# RTS5918 register map
Vendor: Realtek Semiconductor Corp.; Series: RTS5918 Series; File version: 1.00
CPU: ARMV8MML r0p0, little endian, MPU, FPU, VTOR, 3 interrupt priority bits, 8 SAU regions
Registers are 32-bit, read-write, reset 0x0 unless marked. A register's access mark holds for its fields unless they carry their own. Offsets are from the block's base; [hi:lo] are bit positions; {n}, {i} and the like mark numbered series; 'fields as' and 'values as' point back to an identical list.

## PWMLED0 — PWMLED Controller
Base 0x40253D00
Same registers: PWMLED1 0x40253E00
0x00 MODE
  [1:0] SEL — Mode Selection
    0=OFF (PWMLED ouput is off); 1=BREATHING (PWMLED is under breathing mode); 2=BLINKING (PWMLED is under blinking mode); 3=ALWAYS_ON (PWMLED ouput is always on)
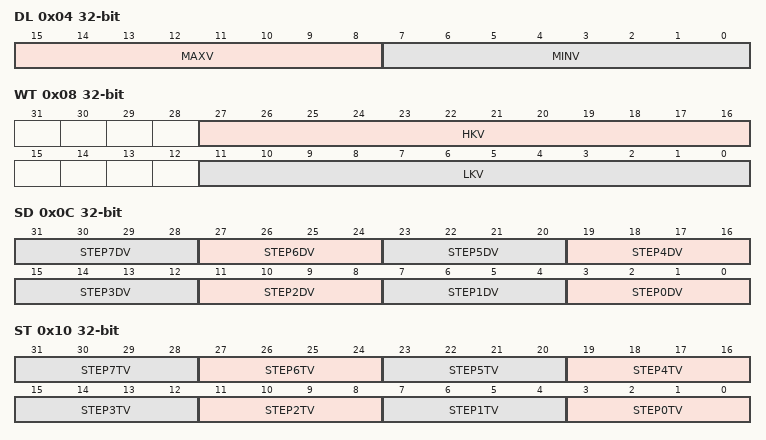
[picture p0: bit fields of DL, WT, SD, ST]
0x04 DL — DUTY LIMIT REGISTER
  [15:8] MAXV — Maximum Duty Cycle
  [7:0] MINV — Minimum Duty Cycle
0x08 WT — WAIT TIME REGISTER
  [27:16] HKV — High wait-time
  [11:0] LKV — Low wait-time
0x0C SD — STEP DUTY REGISTER
  [4n+3:4n] STEP{n}DV (n=0..7) — Step{n} Duty Value
0x10 ST — STEP TIME REGISTER
  [4n+3:4n] STEP{n}TV (n=0..7) — Step{n} Time Value
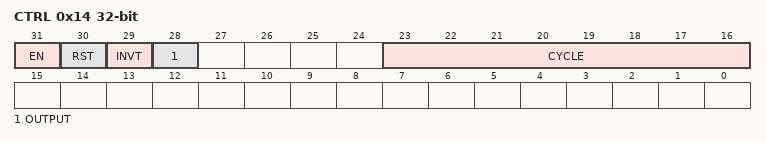
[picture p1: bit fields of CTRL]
0x14 CTRL — CONTROL REGISTER
  [31] EN — Enable PWMLED Controller
    0=DISABLE (Disable PWMLED Controller); 1=ENABLE (Enable PWMLED Controller)
  [30] RST — Reset PWM LED Controller
    0=DO_NOTHING; 1=RESET (Reset PWM LED controller)
  [29] INVT — Output Inverter Control
    0=NORMAL (PWM output is not invert); 1=INVERT (PWM output is invert)
  [28] OUTPUT — Control the output method
    0=ALWAYS_ON (Output is always on); 1=BY_CYCLE (Output is stop when entire cycle is finished)
  [23:16] CYCLE — The number of output cycle

## TACHO0 — Tachometer Controller
Base 0x40251F00
Same registers: TACHO{n} {0x40251F00+0x100*n} (n=1..13)
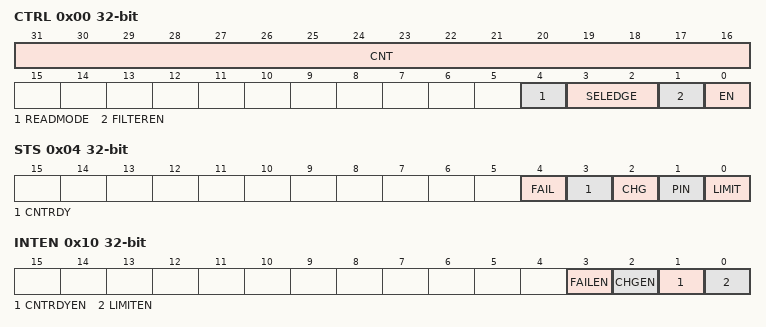
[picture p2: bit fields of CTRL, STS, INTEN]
0x00 CTRL — CONTROL REGISTER
  [31:16] CNT ro — Counter of Tachometer
  [4] READMODE — Select Reading Mode of Tachometer
    0=LOW_TO_HIGH (Counter is incremented when input transitions from low-to-high); 1=RISING_EDGE (Counter is incremented on the rising edge of the 100KHz input)
  [3:2] SELEDGE — Select Edges of Tachometer
    0=x2 (x2 edges (1/2 TACH period)); 1=x3 (x3 edges (1/2 TACH period)); 2=x5 (x5 edges (2 TACH period)); 3=x9 (x9 edges (4 TACH period))
  [1] FILTEREN — Enable Filter of Tachometer
    0=DISABLE (Disabled filter); 1=ENABLE (Enabled filter)
  [0] EN — Enable Tachometer Controller
    0=DISABLE (Disable tachometer controller); 1=ENABLE (Enabled tachometer controller)
0x04 STS — STATUS REGISTER
  [4] FAIL — Tachometer Failed
    0=WORK (Tachometer is working); 1=FAIL (Tachometer is failed)
  [3] CNTRDY — Status of Count Ready
    0=NOT_READY (Tachometer is not ready to count); 1=READY (Tachometer is ready to count)
  [2] CHG — Tachometer Input Changes Its Status
    0=STABLE (Tachometer input status is stable); 1=CHANGED (Tachometer input status is changed)
  [1] PIN ro — Pin Status of Tachometer
    0=LOW (Tachometer input pin is low); 1=HIGH (Tachometer input pin is high)
  [0] LIMIT — Limit status of Tachometer
    0=WITHIN (Counter is within limit); 1=OUTSIDE (Counter is outside of limit)
0x08 LIMITH — HIGH-LIMIT REGISTER
  [15:0] VAL — High limit value
0x0C LIMITL — LOW-LIMIT REGISTER
  [15:0] VAL — Low limit value
0x10 INTEN — INTERRUPT ENABLE REGISTER
  [3] FAILEN — Tacho Failed Interrupt Enable
    0=DISABLE (Disabled tacho failed interrupt); 1=ENABLE (Enabled tacho failed interrupt)
  [2] CHGEN — Input Change Interrupt Enable
    0=DISABLE (Disabled input change interrupt); 1=ENABLE (Enabled input change interrupt)
  [1] CNTRDYEN — Ready to count Interrupt Enable
    0=DISABLE (Disabled ready to count interrupt); 1=ENABLE (Enabled ready to count interrupt)
  [0] LIMITEN — Limit Interrupt Enable
    0=DISABLE (Disabled limit interrupt); 1=ENABLE (Enabled limit interrupt)
0x14 THRESHOLD — TACHO THRESHOLD REGISTER
0x18 TIMEOUT — TACHO TIMEOUT REGISTER

## ADC — 12-bit ADC Controller
Base 0x40251900
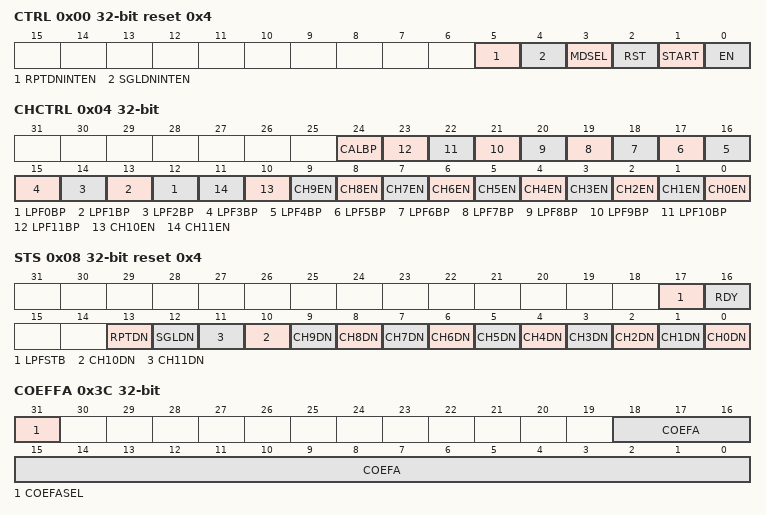
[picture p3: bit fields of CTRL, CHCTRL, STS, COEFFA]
0x00 CTRL reset 0x4 — CONTROL REGISTER
  [5] RPTDNINTEN — Enable Repeat Done Interrupt
    0=DISABLE (Disable repeat done interrupt); 1=ENABLE (Enable repeat done interrupt)
  [4] SGLDNINTEN — Enable Single Done Interrupt
    0=DISABLE (Disable single done interrupt); 1=ENABLE (Enable single done interrupt)
  [3] MDSEL — Conversion Mode Selection
    0=SINGLE_MODE (Performed ADC conversion only one time); 1=REPEAT_MODE (Performed ADC conversions continuously)
  [2] RST — Reset ADC Controller
    0=RESET (Hold ADC controller in reset); 1=DO_NOTHING
  [1] START — Start ADC Conversion
    0=DO_NOTHING; 1=START (Start ADC scan conversions)
  [0] EN — Enable ADC Controller
    0=DISABLE (Disable ADC controller); 1=ENABLE (Enable ADC controller)
0x04 CHCTRL — CHANNEL CONTROL REGISTER
  [24] CALBP — Bypass Linear Calibration
    0=THROUGH (Through linear calibration); 1=BYPASS (Bypass linear calibration)
  [n+12] LPF{n}BP (n=0..11) — Bypass ADC Channel Low-Pass Filter
    0=THROUGH (Through Low-Pass Filter); 1=BYPASS (Bypass Low-Pass Filter)
  [n] CH{n}EN (n=1..11) — Conversion of ADC Channel Complete
    0=DISABLE (Disable ADC channel); 1=ENABLE (Enable ADC channel)
  [0] CH0EN — Enable ADC Channel
    values as CH1EN
0x08 STS reset 0x4 — STATUS REGISTER
  [17] LPFSTB ro — Low-Pass Filter Stable
    0=NOT_STABLE (Low-pass filter data is not stable); 1=STABLE (Low-pass filter data is stable)
  [16] RDY ro — ADC Ready to Conversion
    0=NOT_READY (ADC is not ready to start after power-on); 1=READY (ADC is ready to start after power-on)
  [13] RPTDN — Repeat Conversion Completed
    0=NOT_FIN (Repeat conversion is not completed); 1=DONE (Repeat conversion is completed)
  [12] SGLDN — Single Conversion Completed
    0=NOT_FIN (Single conversion is not completed); 1=DONE (Single conversion is completed)
  [n] CH{n}DN (n=0..11) — Conversion of ADC Channel Complete
    0=NOT_FIN (Conversion of ADC channel is not complete); 1=DONE (Conversion of ADC channel is complete)
{0xC+4i} CHDATA[{i}] (i=0..11) — ADC channel[{i}] Data
  [11:0] RESULT — Conversion Result of Corresponding ADC Channel
0x3C COEFFA — ADC COEFFICIENT A
  [31] COEFASEL — Enable FW Write Data to Coefficient A
    0=DISABLE (Disable FW Write Data to Coefficient A); 1=ENABLE (Enable FW Write Data to Coefficient A)
  [18:0] COEFA — 19 Bit Coefficient A
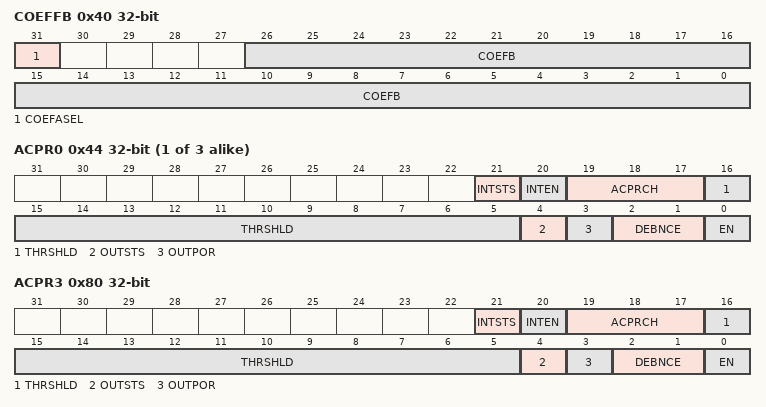
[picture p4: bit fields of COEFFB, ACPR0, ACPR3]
0x40 COEFFB — ADC COEFFICIENT B
  [31] COEFASEL — Enable FW Write Data to Coefficient B
    0=DISABLE (Disable FW Write Data to Coefficient B); 1=ENABLE (Enable FW Write Data to Coefficient B)
  [26:0] COEFB — 27 Bit Coefficient B
{0x44+4i} ACPR{i} (i=0..2) — ADC COMPARATOR 0 REGISTER
  [21] INTSTS — Enable ADC Comparator Interrupt Status
  [20] INTEN — Enable ADC Comparator Interrupt
    0=DISABLE (Disable ADC Comparator Interrupt); 1=ENABLE (Enable ADC Comparator Interrupt)
  [19:17] ACPRCH — ADC Comparator Channel Select
  [16:5] THRSHLD — ADC Comparator Threshold
  [4] OUTSTS ro — ADC Comparator Output Status
  [3] OUTPOR — ADC Comparator Output Polarity
    0=LOW (Active Low); 1=HIGH (Active High)
  [2:1] DEBNCE — ADC Comparator Debounce
    0=NONE (No Debounce (Sample 1 time)); 1=LV1 (Debounce 16ms (Sample 2 times)); 2=LV2 (Debounce 32ms (Sample 4 times)); 3=LV3 (Debounce 64ms (Sample 8 times))
  [0] EN — Enable ADC Comparator
    0=DISABLE (Disable ADC Comparator); 1=ENABLE (Enable ADC Comparator)
0x80 ACPR3 — ADC COMPARATOR 0 REGISTER
  fields as ACPR0
